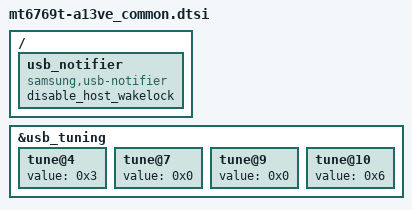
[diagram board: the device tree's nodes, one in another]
/* Generated by Samsung for MTK vendor board
 * If these files should be changed, then please make a sync with MTK
*/
#include "display_lcd_a13ve_common.dtsi"

/* Add Samsung configuration over here */
/ {
	fragment@model {
		target-path = "/";
		__overlay__ {
			usb_notifier {
				compatible = "samsung,usb-notifier";
				disable_host_wakelock;
			};
		};
	};
};

&usb_tuning {
	/* term_vref_sel */
	tune@4 {
		value = <0x3>;
	};
	/* hstx_srctrl */
	tune@7 {
		value = <0x0>;
	};
	/* sqth */
	tune@9 {
		value = <0x0>;
	};
	/* discth */
	tune@10 {
		value = <0x6>;
	};
};
